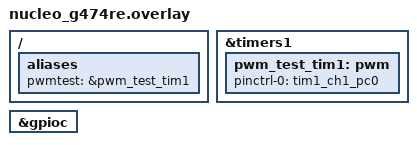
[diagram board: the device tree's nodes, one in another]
/*
 * Fixed 50% PWM @ 20kHz test - board overlay (NUCLEO-G474RE)
 *
 * Pin map:
 *   PWM output (TIM1_CH1) -> PC0
 */

&timers1 {
	status = "okay";

	pwm_test_tim1: pwm {
		status = "okay";
		pinctrl-0 = <&tim1_ch1_pc0>;
		pinctrl-names = "default";
	};
};

&gpioc {
	status = "okay";
};

/ {
	aliases {
		pwmtest = &pwm_test_tim1;
	};
};
